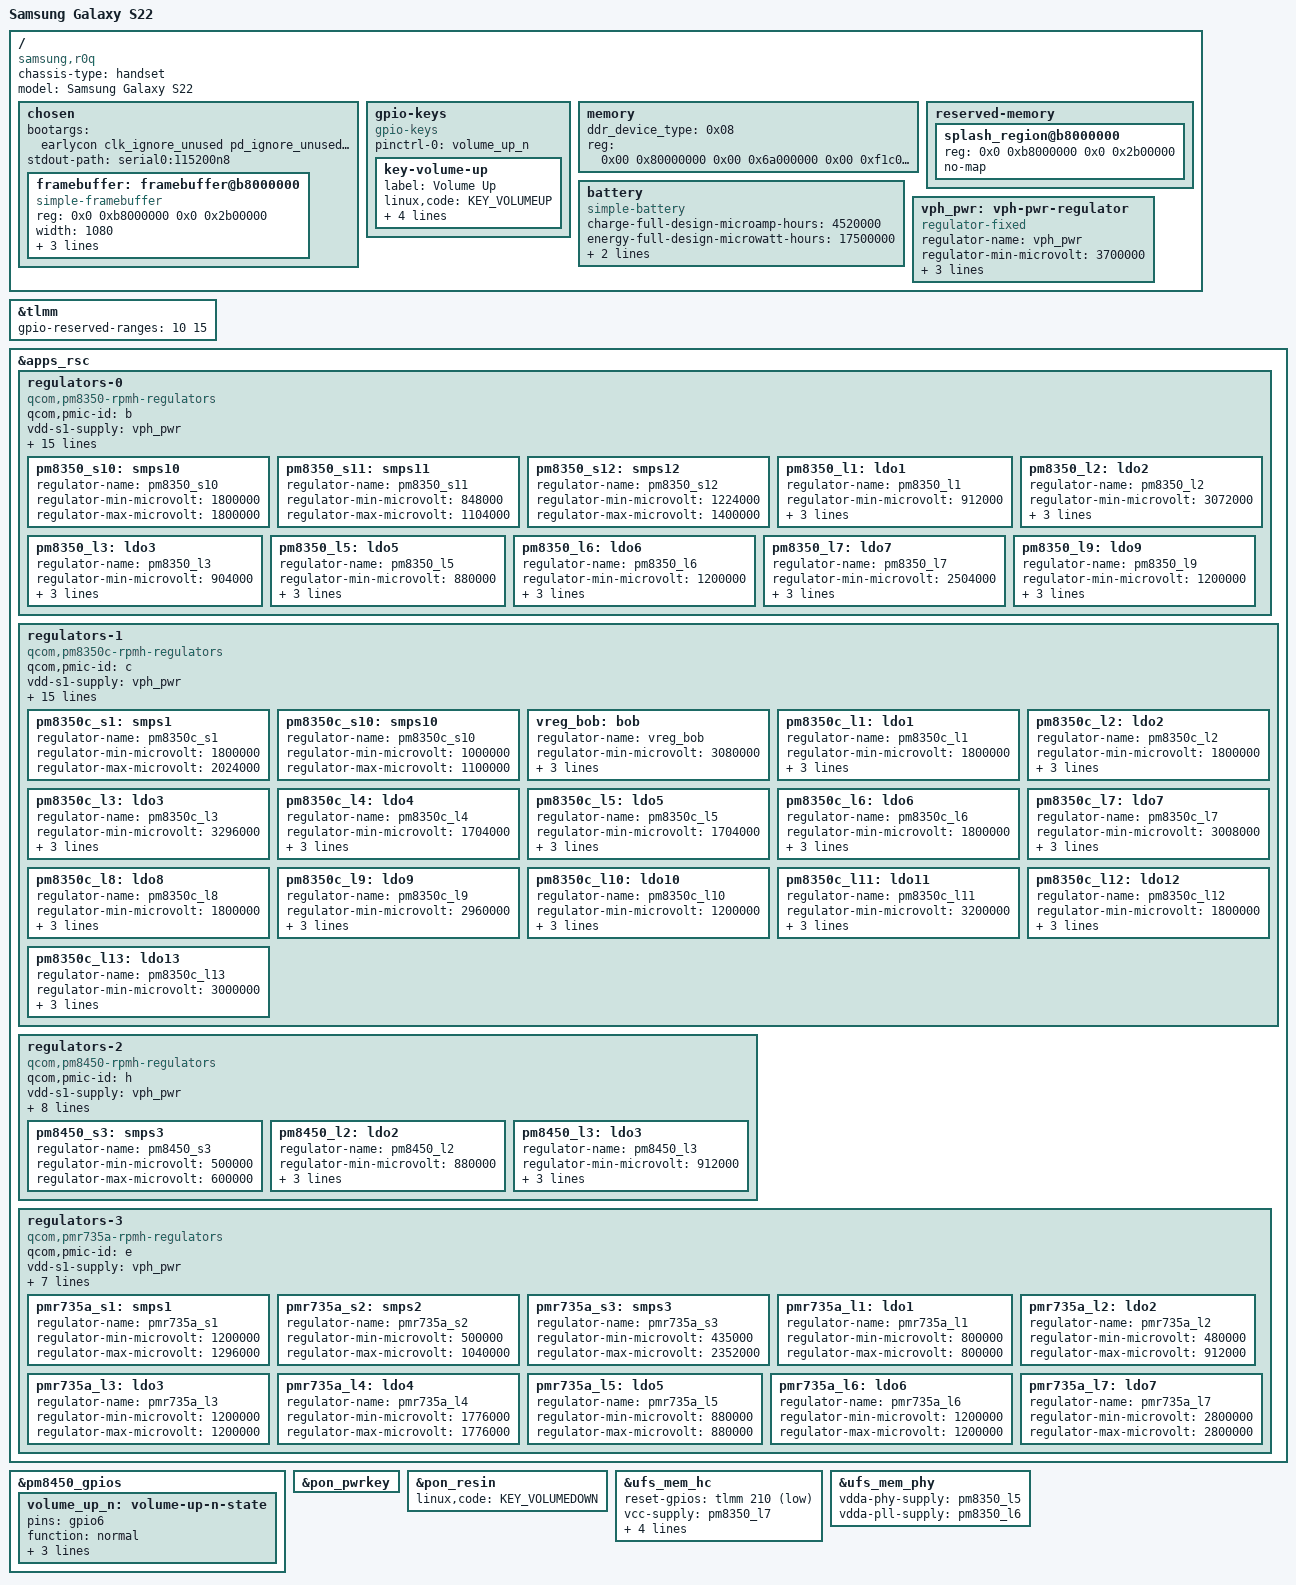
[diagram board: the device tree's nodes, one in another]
// SPDX-License-Identifier: GPL-2.0-only

/dts-v1/;

#include <dt-bindings/regulator/qcom,rpmh-regulator.h>

#include "sm8450.dtsi"
#include "pm8350.dtsi"
#include "pm8350b.dtsi"
#include "pm8350c.dtsi"
#include "pm8450.dtsi"
#include "pmk8350.dtsi"
#include "pmr735a.dtsi"

/ {
    chassis-type = "handset";
    model = "Samsung Galaxy S22";
    compatible = "samsung,r0q", "qcom,sm8450";

    chosen {
        #address-cells = <2>;
        #size-cells = <2>;
        ranges;

        bootargs = "earlycon clk_ignore_unused pd_ignore_unused console=tty0";
        stdout-path = "serial0:115200n8";
    
        framebuffer: framebuffer@b8000000 {
            compatible = "simple-framebuffer";
            reg = <0x0 0xb8000000 0x0 0x2b00000>;
            width = <1080>;
            height = <2340>;
            stride = <(1080 * 4)>;
            format = "a8r8g8b8";
            status = "okay";
        };
    };

    gpio-keys {
    	compatible = "gpio-keys";
    	pinctrl-0 = <&volume_up_n>;
    	pinctrl-names = "default";
    
    	key-volume-up {
    		label = "Volume Up";
    		linux,code = <KEY_VOLUMEUP>;
    		gpios = <&pm8450_gpios 6 GPIO_ACTIVE_LOW>;
    		debounce-interval = <15>;
    		linux,can-disable;
    		wakeup-source;
    	};
    };

    memory {
    	ddr_device_type = <0x08>;
    	device_type = "memory";
    	reg = <0x00 0x80000000 0x00 0x6a000000 0x00 0xf1c00000 0x00 0xe400000 0x08 0x00 0x00 0x3ab00000 0x08 0x40000000 0x01 0x40000000 0x08 0x3b100000 0x00 0x1e00000>;
    };

    reserved-memory {
		splash_region@b8000000 {
			reg = <0x0 0xb8000000 0x0 0x2b00000>;
			no-map;
		};
    };

    battery: battery {
        compatible = "simple-battery";
        charge-full-design-microamp-hours = <4520000>;
        energy-full-design-microwatt-hours = <17500000>;
        voltage-min-design-microvolt = <3400000>;
        voltage-max-design-microvolt = <4460000>;
    };

    vph_pwr: vph-pwr-regulator {
    	compatible = "regulator-fixed";
    	regulator-name = "vph_pwr";
    	regulator-min-microvolt = <3700000>;
    	regulator-max-microvolt = <3700000>;
    
    	regulator-always-on;
    	regulator-boot-on;
    };
};

&tlmm {
    gpio-reserved-ranges = <10 15>;
};

&apps_rsc {
	regulators-0 {
		compatible = "qcom,pm8350-rpmh-regulators";
		qcom,pmic-id = "b";

		vdd-s1-supply = <&vph_pwr>;
		vdd-s2-supply = <&vph_pwr>;
		vdd-s3-supply = <&vph_pwr>;
		vdd-s4-supply = <&vph_pwr>;
		vdd-s5-supply = <&vph_pwr>;
		vdd-s6-supply = <&vph_pwr>;
		vdd-s7-supply = <&vph_pwr>;
		vdd-s8-supply = <&vph_pwr>;
		vdd-s9-supply = <&vph_pwr>;
		vdd-s10-supply = <&vph_pwr>;
		vdd-s11-supply = <&vph_pwr>;
		vdd-s12-supply = <&vph_pwr>;

		vdd-l1-l4-supply = <&pm8350_s11>;
		vdd-l2-l7-supply = <&vreg_bob>;
		vdd-l3-l5-supply = <&pm8350_s11>;
		vdd-l6-l9-l10-supply = <&pm8350_s12>;

		/*
		 * ARC regulators:
		 * s5 - gfx.lvl
		 * l8 - lcx.lvl
		 */

		pm8350_s10: smps10 {
			regulator-name = "pm8350_s10";
			regulator-min-microvolt = <1800000>;
			regulator-max-microvolt = <1800000>;
		};

		pm8350_s11: smps11 {
			regulator-name = "pm8350_s11";
			regulator-min-microvolt = <848000>;
			regulator-max-microvolt = <1104000>;
		};

		pm8350_s12: smps12 {
			regulator-name = "pm8350_s12";
			regulator-min-microvolt = <1224000>;
			regulator-max-microvolt = <1400000>;
		};

		pm8350_l1: ldo1 {
			regulator-name = "pm8350_l1";
			regulator-min-microvolt = <912000>;
			regulator-max-microvolt = <920000>;
			regulator-initial-mode = <RPMH_REGULATOR_MODE_HPM>;
		};

		pm8350_l2: ldo2 {
			regulator-name = "pm8350_l2";
			regulator-min-microvolt = <3072000>;
			regulator-max-microvolt = <3072000>;
			regulator-initial-mode = <RPMH_REGULATOR_MODE_HPM>;
		};

		pm8350_l3: ldo3 {
			regulator-name = "pm8350_l3";
			regulator-min-microvolt = <904000>;
			regulator-max-microvolt = <904000>;
			regulator-initial-mode = <RPMH_REGULATOR_MODE_HPM>;
		};

		pm8350_l5: ldo5 {
			regulator-name = "pm8350_l5";
			regulator-min-microvolt = <880000>;
			regulator-max-microvolt = <912000>;
			regulator-initial-mode = <RPMH_REGULATOR_MODE_HPM>;
		};

		pm8350_l6: ldo6 {
			regulator-name = "pm8350_l6";
			regulator-min-microvolt = <1200000>;
			regulator-max-microvolt = <1200000>;
			regulator-initial-mode = <RPMH_REGULATOR_MODE_HPM>;
		};

		pm8350_l7: ldo7 {
			regulator-name = "pm8350_l7";
			regulator-min-microvolt = <2504000>;
			regulator-max-microvolt = <2504000>;
			regulator-initial-mode = <RPMH_REGULATOR_MODE_HPM>;
		};

		pm8350_l9: ldo9 {
			regulator-name = "pm8350_l9";
			regulator-min-microvolt = <1200000>;
			regulator-max-microvolt = <1200000>;
			regulator-initial-mode = <RPMH_REGULATOR_MODE_HPM>;
		};
	};

	regulators-1 {
		compatible = "qcom,pm8350c-rpmh-regulators";
		qcom,pmic-id = "c";

		vdd-s1-supply = <&vph_pwr>;
		vdd-s2-supply = <&vph_pwr>;
		vdd-s3-supply = <&vph_pwr>;
		vdd-s4-supply = <&vph_pwr>;
		vdd-s5-supply = <&vph_pwr>;
		vdd-s6-supply = <&vph_pwr>;
		vdd-s7-supply = <&vph_pwr>;
		vdd-s8-supply = <&vph_pwr>;
		vdd-s9-supply = <&vph_pwr>;
		vdd-s10-supply = <&vph_pwr>;

		vdd-l1-l12-supply = <&pm8350c_s1>;
		vdd-l2-l8-supply = <&pm8350c_s1>;
		vdd-l3-l4-l5-l7-l13-supply = <&vreg_bob>;
		vdd-l6-l9-l11-supply = <&vreg_bob>;
		vdd-l10-supply = <&pm8350_s12>;

		vdd-bob-supply = <&vph_pwr>;

		/*
		 * ARC regulators:
		 * s2 - mxc.lvl
		 * s4 - mss.lvl
		 * s6 - cx.lvl
		 */

		pm8350c_s1: smps1 {
			regulator-name = "pm8350c_s1";
			regulator-min-microvolt = <1800000>;
			regulator-max-microvolt = <2024000>;
		};

		pm8350c_s10: smps10 {
			regulator-name = "pm8350c_s10";
			regulator-min-microvolt = <1000000>;
			regulator-max-microvolt = <1100000>;
		};

		vreg_bob: bob {
			regulator-name = "vreg_bob";
			regulator-min-microvolt = <3080000>;
			regulator-max-microvolt = <3960000>;
			regulator-initial-mode = <RPMH_REGULATOR_MODE_AUTO>;
		};

		pm8350c_l1: ldo1 {
			regulator-name = "pm8350c_l1";
			regulator-min-microvolt = <1800000>;
			regulator-max-microvolt = <1800000>;
			regulator-initial-mode = <RPMH_REGULATOR_MODE_HPM>;
		};

		pm8350c_l2: ldo2 {
			regulator-name = "pm8350c_l2";
			regulator-min-microvolt = <1800000>;
			regulator-max-microvolt = <1800000>;
			regulator-initial-mode = <RPMH_REGULATOR_MODE_HPM>;
		};

		pm8350c_l3: ldo3 {
			regulator-name = "pm8350c_l3";
			regulator-min-microvolt = <3296000>;
			regulator-max-microvolt = <3304000>;
			regulator-initial-mode = <RPMH_REGULATOR_MODE_HPM>;
		};

		pm8350c_l4: ldo4 {
			regulator-name = "pm8350c_l4";
			regulator-min-microvolt = <1704000>;
			regulator-max-microvolt = <3000000>;
			regulator-initial-mode = <RPMH_REGULATOR_MODE_HPM>;
		};

		pm8350c_l5: ldo5 {
			regulator-name = "pm8350c_l5";
			regulator-min-microvolt = <1704000>;
			regulator-max-microvolt = <3000000>;
			regulator-initial-mode = <RPMH_REGULATOR_MODE_HPM>;
		};

		pm8350c_l6: ldo6 {
			regulator-name = "pm8350c_l6";
			regulator-min-microvolt = <1800000>;
			/* Originally max = 3008000 but SDHCI expects 2960000 */
			regulator-max-microvolt = <2960000>;
			regulator-initial-mode = <RPMH_REGULATOR_MODE_HPM>;
		};

		pm8350c_l7: ldo7 {
			regulator-name = "pm8350c_l7";
			regulator-min-microvolt = <3008000>;
			regulator-max-microvolt = <3304000>;
			regulator-initial-mode = <RPMH_REGULATOR_MODE_HPM>;
		};

		pm8350c_l8: ldo8 {
			regulator-name = "pm8350c_l8";
			regulator-min-microvolt = <1800000>;
			regulator-max-microvolt = <1800000>;
			regulator-initial-mode = <RPMH_REGULATOR_MODE_HPM>;
		};

		pm8350c_l9: ldo9 {
			regulator-name = "pm8350c_l9";
			regulator-min-microvolt = <2960000>;
			/* Originally max = 3008000 but SDHCI expects 2960000 */
			regulator-max-microvolt = <2960000>;
			regulator-initial-mode = <RPMH_REGULATOR_MODE_HPM>;
		};

		pm8350c_l10: ldo10 {
			regulator-name = "pm8350c_l10";
			regulator-min-microvolt = <1200000>;
			regulator-max-microvolt = <1220000>;
			regulator-initial-mode = <RPMH_REGULATOR_MODE_HPM>;
		};

		pm8350c_l11: ldo11 {
			regulator-name = "pm8350c_l11";
			regulator-min-microvolt = <3200000>;
			regulator-max-microvolt = <3200000>;
			regulator-initial-mode = <RPMH_REGULATOR_MODE_HPM>;
		};

		pm8350c_l12: ldo12 {
			regulator-name = "pm8350c_l12";
			regulator-min-microvolt = <1800000>;
			regulator-max-microvolt = <1968000>;
			regulator-initial-mode = <RPMH_REGULATOR_MODE_HPM>;
		};

		pm8350c_l13: ldo13 {
			regulator-name = "pm8350c_l13";
			regulator-min-microvolt = <3000000>;
			regulator-max-microvolt = <3000000>;
			regulator-initial-mode = <RPMH_REGULATOR_MODE_HPM>;
		};
	};

	regulators-2 {
		compatible = "qcom,pm8450-rpmh-regulators";
		qcom,pmic-id = "h";

		vdd-s1-supply = <&vph_pwr>;
		vdd-s2-supply = <&vph_pwr>;
		vdd-s3-supply = <&vph_pwr>;
		vdd-s4-supply = <&vph_pwr>;
		vdd-s5-supply = <&vph_pwr>;
		vdd-s6-supply = <&vph_pwr>;

		vdd-l2-supply = <&vreg_bob>;
		vdd-l3-supply = <&vreg_bob>;
		vdd-l4-supply = <&vreg_bob>;

		/*
		 * ARC regulators:
		 * S2 - ebi.lvl
		 * S4 - mmcx.lvl
		 * S6 - mx.lvl
		 * L1 - lmx.lvl
		 */

		pm8450_s3: smps3 {
			regulator-name = "pm8450_s3";
			regulator-min-microvolt = <500000>;
			regulator-max-microvolt = <600000>;
		};

		pm8450_l2: ldo2 {
			regulator-name = "pm8450_l2";
			regulator-min-microvolt = <880000>;
			regulator-max-microvolt = <912000>;
			regulator-initial-mode = <RPMH_REGULATOR_MODE_HPM>;
		};

		pm8450_l3: ldo3 {
			regulator-name = "pm8450_l3";
			regulator-min-microvolt = <912000>;
			regulator-max-microvolt = <912000>;
			regulator-initial-mode = <RPMH_REGULATOR_MODE_HPM>;
		};
	};

	regulators-3 {
		compatible = "qcom,pmr735a-rpmh-regulators";
		qcom,pmic-id = "e";

		vdd-s1-supply = <&vph_pwr>;
		vdd-s2-supply = <&vph_pwr>;
		vdd-s3-supply = <&vph_pwr>;

		vdd-l1-l2-supply = <&pmr735a_s2>;
		vdd-l3-supply = <&pmr735a_s1>;
		vdd-l4-supply = <&pm8350c_s1>;
		vdd-l5-l6-supply = <&pm8350c_s1>;
		vdd-l7-bob-supply = <&vreg_bob>;

		pmr735a_s1: smps1 {
			regulator-name = "pmr735a_s1";
			regulator-min-microvolt = <1200000>;
			regulator-max-microvolt = <1296000>;
		};

		pmr735a_s2: smps2 {
			regulator-name = "pmr735a_s2";
			regulator-min-microvolt = <500000>;
			regulator-max-microvolt = <1040000>;
		};

		pmr735a_s3: smps3 {
			regulator-name = "pmr735a_s3";
			regulator-min-microvolt = <435000>;
			regulator-max-microvolt = <2352000>;
		};

		pmr735a_l1: ldo1 {
			regulator-name = "pmr735a_l1";
			regulator-min-microvolt = <800000>;
			regulator-max-microvolt = <800000>;
		};

		pmr735a_l2: ldo2 {
			regulator-name = "pmr735a_l2";
			regulator-min-microvolt = <480000>;
			regulator-max-microvolt = <912000>;
		};

		pmr735a_l3: ldo3 {
			regulator-name = "pmr735a_l3";
			regulator-min-microvolt = <1200000>;
			regulator-max-microvolt = <1200000>;
		};

		pmr735a_l4: ldo4 {
			regulator-name = "pmr735a_l4";
			regulator-min-microvolt = <1776000>;
			regulator-max-microvolt = <1776000>;
		};

		pmr735a_l5: ldo5 {
			regulator-name = "pmr735a_l5";
			regulator-min-microvolt = <880000>;
			regulator-max-microvolt = <880000>;
		};

		pmr735a_l6: ldo6 {
			regulator-name = "pmr735a_l6";
			regulator-min-microvolt = <1200000>;
			regulator-max-microvolt = <1200000>;
		};

		pmr735a_l7: ldo7 {
			regulator-name = "pmr735a_l7";
			regulator-min-microvolt = <2800000>;
			regulator-max-microvolt = <2800000>;
		};
	};
};

&pm8450_gpios {
	volume_up_n: volume-up-n-state {
		pins = "gpio6";
		function = "normal";
		power-source = <1>;
		bias-pull-up;
		input-enable;
	};
};

&pon_pwrkey {
	status = "okay";
};

&pon_resin {
	status = "okay";
	linux,code = <KEY_VOLUMEDOWN>;
};

&ufs_mem_hc {
	status = "okay";

	reset-gpios = <&tlmm 210 GPIO_ACTIVE_LOW>;

	vcc-supply = <&pm8350_l7>;
	vcc-max-microamp = <1100000>;
	vccq-supply = <&pm8350_l9>;
	vccq-max-microamp = <1200000>;
	vdd-hba-supply = <&pm8350_l9>;
};

&ufs_mem_phy {
	status = "okay";

	vdda-phy-supply = <&pm8350_l5>;
	vdda-pll-supply = <&pm8350_l6>;
};
